VERSION "ParkAssistCAN"

NS_ :

BS_:

BU_: ACM CGM EPAS_P ESP IBM OCS RCM SAS TestTool VDM Vector_XXX

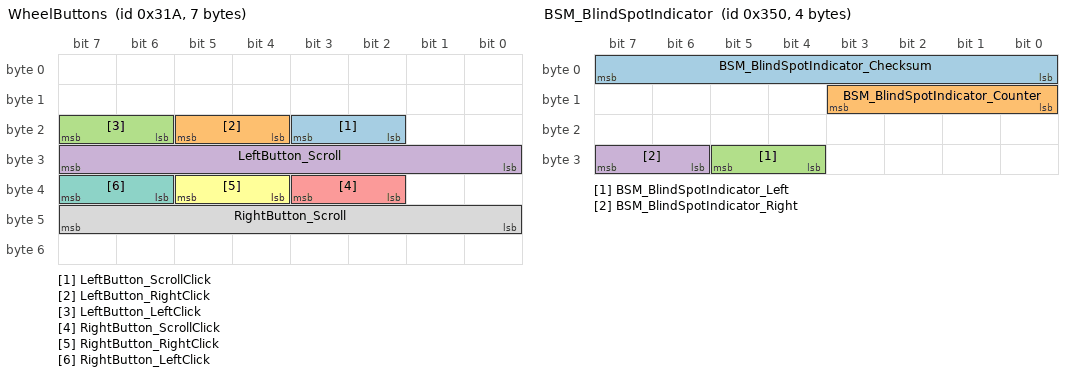
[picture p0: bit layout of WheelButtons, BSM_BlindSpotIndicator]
BO_ 794 WheelButtons: 7 XXX
 SG_ LeftButton_ScrollClick : 19|2@0+ (1,0) [0|3] "" XXX
 SG_ LeftButton_RightClick : 21|2@0+ (1,0) [0|3] "" XXX
 SG_ LeftButton_LeftClick : 22|2@1+ (1,0) [0|3] "" XXX
 SG_ LeftButton_Scroll : 31|8@0+ (1,0) [0|255] "" XXX
 SG_ RightButton_ScrollClick : 35|2@0+ (1,0) [0|3] "" XXX
 SG_ RightButton_RightClick : 37|2@0+ (1,0) [0|3] "" XXX
 SG_ RightButton_LeftClick : 38|2@1+ (1,0) [0|3] "" XXX
 SG_ RightButton_Scroll : 47|8@0+ (1,0) [0|255] "" XXX

BO_ 848 BSM_BlindSpotIndicator: 4 XXX
 SG_ BSM_BlindSpotIndicator_Checksum : 0|8@1+ (1,0) [0|255] "" XXX
 SG_ BSM_BlindSpotIndicator_Counter : 11|4@0+ (1,0) [0|15] "" XXX
 SG_ BSM_BlindSpotIndicator_Left : 29|2@0+ (1,0) [0|3] "" XXX
 SG_ BSM_BlindSpotIndicator_Right : 30|2@1+ (1,0) [0|3] "" XXX

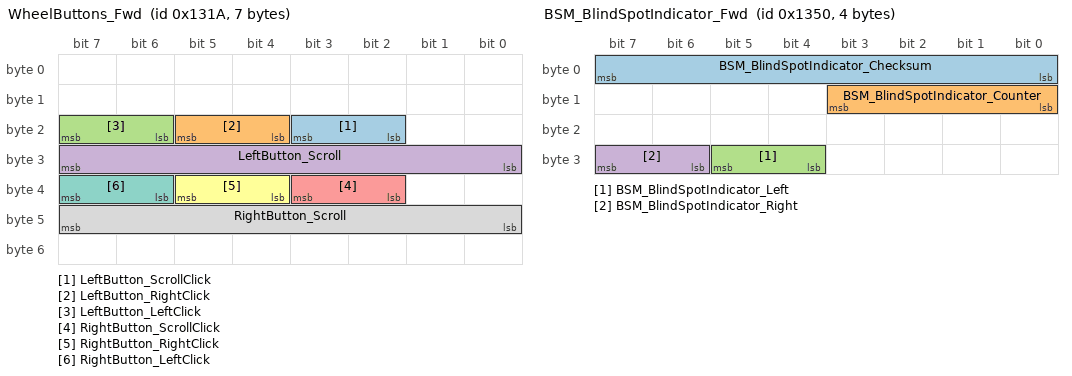
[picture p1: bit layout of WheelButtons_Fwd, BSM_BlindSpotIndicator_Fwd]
BO_ 4890 WheelButtons_Fwd: 7 XXX
 SG_ LeftButton_ScrollClick : 19|2@0+ (1,0) [0|3] "" XXX
 SG_ LeftButton_RightClick : 21|2@0+ (1,0) [0|3] "" XXX
 SG_ LeftButton_LeftClick : 22|2@1+ (1,0) [0|3] "" XXX
 SG_ LeftButton_Scroll : 31|8@0+ (1,0) [0|255] "" XXX
 SG_ RightButton_ScrollClick : 35|2@0+ (1,0) [0|3] "" XXX
 SG_ RightButton_RightClick : 37|2@0+ (1,0) [0|3] "" XXX
 SG_ RightButton_LeftClick : 38|2@1+ (1,0) [0|3] "" XXX
 SG_ RightButton_Scroll : 47|8@0+ (1,0) [0|255] "" XXX

BO_ 4944 BSM_BlindSpotIndicator_Fwd: 4 XXX
 SG_ BSM_BlindSpotIndicator_Checksum : 0|8@1+ (1,0) [0|255] "" XXX
 SG_ BSM_BlindSpotIndicator_Counter : 11|4@0+ (1,0) [0|15] "" XXX
 SG_ BSM_BlindSpotIndicator_Left : 29|2@0+ (1,0) [0|3] "" XXX
 SG_ BSM_BlindSpotIndicator_Right : 30|2@1+ (1,0) [0|3] "" XXX

VAL_ 848 BSM_BlindSpotIndicator_Left 0 "OFF" 1 "OBJECT_DETECTED" 2 "ACTIVE_WARNING" ;
VAL_ 848 BSM_BlindSpotIndicator_Right 0 "OFF" 1 "OBJECT_DETECTED" 2 "ACTIVE_WARNING" ;
VAL_ 4944 BSM_BlindSpotIndicator_Left 0 "OFF" 1 "OBJECT_DETECTED" 2 "ACTIVE_WARNING" ;
VAL_ 4944 BSM_BlindSpotIndicator_Right 0 "OFF" 1 "OBJECT_DETECTED" 2 "ACTIVE_WARNING" ;
